AUTOSAR XML (schema 4-0-3)
package /ErrM/ApplicationSwComponentTypes
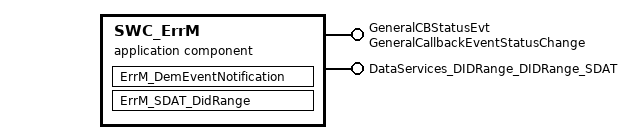
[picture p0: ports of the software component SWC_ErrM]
  application sw component type SWC_ErrM
    provide port GeneralCBStatusEvt: server-com-spec{operation=EventStatusChanged, queue-length=1}, provided-interface=GeneralCallbackEventStatusChange
    provide port DataServices_DIDRange_DIDRange_SDAT: server-com-spec{operation=ReadDidData, queue-length=1}, provided-interface=DataServices_DIDRange_DIDRange_SDAT
    behavior SwcIB_ErrM
      operation invoked event OIE_GeneralCallbackEventStatusChange: start-on-event=ErrM_DemEventNotification, operation=GeneralCBStatusEvt.EventStatusChanged
      operation invoked event OIE_ErrM_SDAT_DidRange: start-on-event=ErrM_SDAT_DidRange, operation=DataServices_DIDRange_DIDRange_SDAT.ReadDidData
      runnable ErrM_DemEventNotification
      runnable ErrM_SDAT_DidRange: can-be-invoked-concurrently=true
